AUTOSAR XML (schema 00044)
package /ComponentTypes
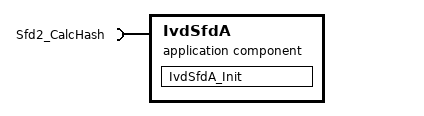
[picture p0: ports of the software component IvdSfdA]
  application sw component type IvdSfdA
    require port Sfd2_CalcHash: required-com-specs=[CalcHash_Data, CalcHash_Hash, CalcHash_Setup], required-interface=Sfd2_CalcHash
    behavior IvdSfdA_InternalBehavior
      init event SfdA_InitEvent: start-on-event=IvdSfdA_Init
      runnable IvdSfdA_Init
        sync call SC_Sfd2_CalcHash_Data: operation=Sfd2_CalcHash.CalcHash_Data
        sync call SC_Sfd2_CalcHash_Hash: operation=Sfd2_CalcHash.CalcHash_Hash
        sync call SC_Sfd2_CalcHash_Setup: operation=Sfd2_CalcHash.CalcHash_Setup
  swc implementation IvdSfdA_Implementation: vendor-id=75, behavior=IvdSfdA_InternalBehavior
    code-descriptors:
      code Default: artifact-descriptors=autosar-engineering-object=category=SWSRC
    resource consumption ResourceConsumption
      memory section CODE: sw-addrmethod=CODE
